VERSION ""

NS_ :

BS_:

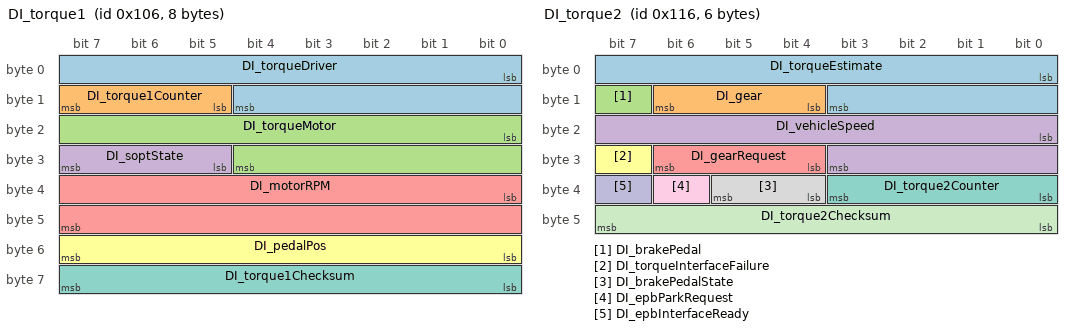
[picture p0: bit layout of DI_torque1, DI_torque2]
BO_ 262 DI_torque1: 8 DI
 SG_ DI_torqueDriver : 0|13@1- (0.25,0) [-750|750] "Nm"  NEO
 SG_ DI_torque1Counter : 13|3@1+ (1,0) [0|0] ""  NEO
 SG_ DI_torqueMotor : 16|13@1- (0.25,0) [-750|750] "Nm"  NEO
 SG_ DI_soptState : 29|3@1+ (1,0) [0|0] ""  NEO
 SG_ DI_motorRPM : 32|16@1- (1,0) [-17000|17000] "RPM"  NEO
 SG_ DI_pedalPos : 48|8@1+ (0.4,0) [0|100] "%"  NEO
 SG_ DI_torque1Checksum : 56|8@1+ (1,0) [0|0] ""  NEO

BO_ 278 DI_torque2: 6 DI
 SG_ DI_torqueEstimate : 0|12@1- (0.5,0) [-750|750] "Nm" NEO
 SG_ DI_gear : 12|3@1+ (1,0) [0|0] "" NEO
 SG_ DI_brakePedal : 15|1@1+ (1,0) [0|0] "" NEO
 SG_ DI_vehicleSpeed : 16|12@1+ (0.05,-25) [-25|179.75] "MPH" NEO
 SG_ DI_gearRequest : 28|3@1+ (1,0) [0|0] "" NEO
 SG_ DI_torqueInterfaceFailure : 31|1@1+ (1,0) [0|0] "" NEO
 SG_ DI_torque2Counter : 32|4@1+ (1,0) [0|0] "" NEO
 SG_ DI_brakePedalState : 36|2@1+ (1,0) [0|0] "" NEO
 SG_ DI_epbParkRequest : 38|1@1+ (1,0) [0|0] "" NEO
 SG_ DI_epbInterfaceReady : 39|1@1+ (1,0) [0|0] "" NEO
 SG_ DI_torque2Checksum : 40|8@1+ (1,0) [0|0] "" NEO

BO_ 504 BrakeMessage: 8 XXX
 SG_ driverBrakeStatus : 2|2@1+ (1,0) [0|3] "" XXX

BO_ 568 STW_ACTN_RQ: 8 STW
 SG_ SpdCtrlLvr_Stat : 0|6@1+ (1,0) [0|0] "" NEO
 SG_ VSL_Enbl_Rq : 6|1@1+ (1,0) [0|0] "" NEO
 SG_ SpdCtrlLvrStat_Inv : 7|1@1+ (1,0) [0|0] "" NEO
 SG_ DTR_Dist_Rq : 8|8@1+ (1,0) [0|200] "" NEO
 SG_ TurnIndLvr_Stat : 16|2@1+ (1,0) [0|0] "" NEO
 SG_ HiBmLvr_Stat : 18|2@1+ (1,0) [0|0] "" NEO
 SG_ WprWashSw_Psd : 20|2@1+ (1,0) [0|0] "" NEO
 SG_ WprWash_R_Sw_Posn_V2 : 22|2@1+ (1,0) [0|0] "" NEO
 SG_ StW_Lvr_Stat : 24|3@1+ (1,0) [0|0] "" NEO
 SG_ StW_Cond_Flt : 27|1@1+ (1,0) [0|0] "" NEO
 SG_ StW_Cond_Psd : 28|2@1+ (1,0) [0|0] "" NEO
 SG_ HrnSw_Psd : 30|2@1+ (1,0) [0|0] "" NEO
 SG_ StW_Sw00_Psd : 32|1@1+ (1,0) [0|0] "" NEO
 SG_ StW_Sw01_Psd : 33|1@1+ (1,0) [0|0] "" NEO
 SG_ StW_Sw02_Psd : 34|1@1+ (1,0) [0|0] "" NEO
 SG_ StW_Sw03_Psd : 35|1@1+ (1,0) [0|0] "" NEO
 SG_ StW_Sw04_Psd : 36|1@1+ (1,0) [0|0] "" NEO
 SG_ StW_Sw05_Psd : 37|1@1+ (1,0) [0|0] "" NEO
 SG_ StW_Sw06_Psd : 38|1@1+ (1,0) [0|0] "" NEO
 SG_ StW_Sw07_Psd : 39|1@1+ (1,0) [0|0] "" NEO
 SG_ StW_Sw08_Psd : 40|1@1+ (1,0) [0|0] "" NEO
 SG_ StW_Sw09_Psd : 41|1@1+ (1,0) [0|0] "" NEO
 SG_ StW_Sw10_Psd : 42|1@1+ (1,0) [0|0] "" NEO
 SG_ StW_Sw11_Psd : 43|1@1+ (1,0) [0|0] "" NEO
 SG_ StW_Sw12_Psd : 44|1@1+ (1,0) [0|0] "" NEO
 SG_ StW_Sw13_Psd : 45|1@1+ (1,0) [0|0] "" NEO
 SG_ StW_Sw14_Psd : 46|1@1+ (1,0) [0|0] "" NEO
 SG_ StW_Sw15_Psd : 47|1@1+ (1,0) [0|0] "" NEO
 SG_ WprSw6Posn : 48|3@1+ (1,0) [0|0] "" NEO
 SG_ MC_STW_ACTN_RQ : 52|4@1+ (1,0) [0|15] "" NEO
 SG_ CRC_STW_ACTN_RQ : 56|8@1+ (1,0) [0|0] "" NEO

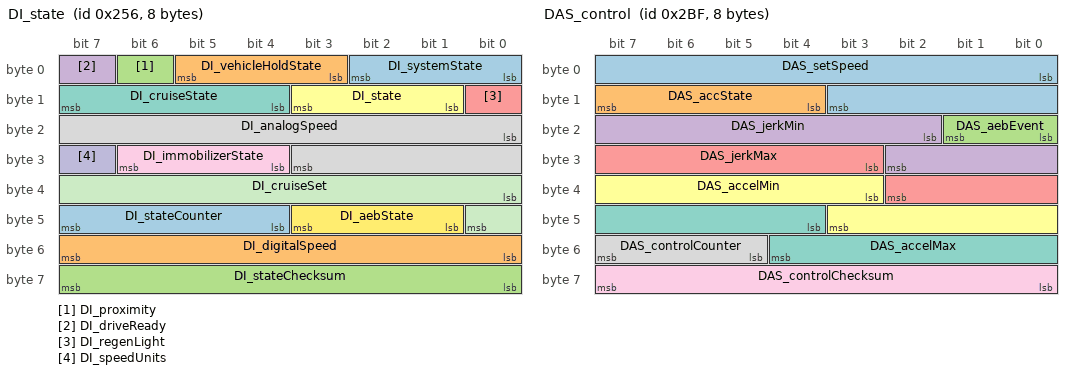
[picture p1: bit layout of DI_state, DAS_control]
BO_ 598 DI_state: 8 DI
 SG_ DI_systemState : 0|3@1+ (1,0) [0|0] ""  NEO
 SG_ DI_vehicleHoldState : 3|3@1+ (1,0) [0|0] ""  NEO
 SG_ DI_proximity : 6|1@1+ (1,0) [0|0] ""  NEO
 SG_ DI_driveReady : 7|1@1+ (1,0) [0|0] ""  NEO
 SG_ DI_regenLight : 8|1@1+ (1,0) [0|0] ""  NEO
 SG_ DI_state : 9|3@1+ (1,0) [0|0] ""  NEO
 SG_ DI_cruiseState : 12|4@1+ (1,0) [0|0] ""  NEO
 SG_ DI_analogSpeed : 16|12@1+ (0.1,0) [0|150] "speed"  NEO
 SG_ DI_immobilizerState : 28|3@1+ (1,0) [0|0] ""  NEO
 SG_ DI_speedUnits : 31|1@1+ (1,0) [0|1] ""  NEO
 SG_ DI_cruiseSet : 32|9@1+ (0.5,0) [0|255.5] "speed"  NEO
 SG_ DI_aebState : 41|3@1+ (1,0) [0|0] ""  NEO
 SG_ DI_stateCounter : 44|4@1+ (1,0) [0|0] ""  NEO
 SG_ DI_digitalSpeed : 48|8@1+ (1,0) [0|250] ""  NEO
 SG_ DI_stateChecksum : 56|8@1+ (1,0) [0|0] ""  NEO

BO_ 703 DAS_control: 8 GTW
 SG_ DAS_setSpeed : 0|12@1+ (0.1,0) [0|409.4] "kph" DI,PM,APS
 SG_ DAS_accState : 12|4@1+ (1,0) [0|0] "" DI,PM,APS
 SG_ DAS_aebEvent : 16|2@1+ (1,0) [0|3] "" DI,PM,APS
 SG_ DAS_jerkMin : 18|9@1+ (0.03,-15.232) [-15.232|0.098] "m/s^3" DI,PM,APS
 SG_ DAS_jerkMax : 27|8@1+ (0.059,0) [0|15.045] "m/s^3" DI,PM,APS
 SG_ DAS_accelMin : 35|9@1+ (0.04,-15) [-15|5.44] "m/s^2" DI,PM,APS
 SG_ DAS_accelMax : 44|9@1+ (0.04,-15) [-15|5.44] "m/s^2" DI,PM,APS
 SG_ DAS_controlCounter : 53|3@1+ (1,0) [0|0] "" DI,PM,APS
 SG_ DAS_controlChecksum : 56|8@1+ (1,0) [0|0] "" DI,PM,APS

BU_: XXX

CM_ "AUTOGENERATED FILE, DO NOT EDIT";

CM_ "Imported file _stellantis_common_ram_dt_generated.dbc starts here";
CM_ "Generated from _stellantis_common.dbc"

CM_ SG_ 258 STEERING_ANGLE_HP "Steering angle high precision";
CM_ SG_ 264 ENGINE_TORQUE "Effective engine torque";
CM_ SG_ 264 EXPECTED_ENGINE_TORQUE "Expected Engine Torque based on target engine speed";
CM_ SG_ 678 LKAS_ICON_COLOR "3 is yellow, 2 is green, 1 is white, 0 is null";
CM_ SG_ 678 LKAS_LANE_LINES "0x01 transparent lines, 0x02 left white, 0x03 right white, 0x04 left yellow with car on top, 0x05 left yellow with car on top, 0x06 both white, 0x07 left yellow, 0x08 left yellow right white, 0x09 right yellow, 0x0a right yellow left white, 0x0b left yellow with car on top right white, 0x0c right yellow with car on top left white, (0x00, 0x0d, 0x0e, 0x0f) null";
CM_ SG_ 678 LKAS_ALERTS "(0x01, 0x02) lane sense off, (0x03, 0x04, 0x06) place hands on steering wheel, 0x07 lane departure detected + place hands on steering wheel, (0x08, 0x09) lane sense unavailable + clean front windshield, 0x0b lane sense and auto high beam unavailable + clean front windshield, 0x0c lane sense unavailable + service required, (0x00, 0x05, 0x0a, 0x0d, 0x0e, 0x0f) null";

CM_ "chrysler_ram_dt.dbc starts here";

CM_ SG_ 133 ACTUAL_GEAR "0xd = P, 0x1-8 = D (actual gear), 0xb = R or N?? TODO find R vs N";
CM_ SG_ 153 ACC_Engaged "SENT BY FORWARD CAMERA 1 = ACTIVE, 3 = ENGAGED, 0 = DISENGAGED/OFF";
CM_ SG_ 166 LKAS_CONTROL_BIT "0=IDLE, 1=HAS 2=LKAS 3=ABSD, 4=TJA, 7=SNA";
CM_ SG_ 250 Auto_High_Beam "1 = HIGH BEAMS OK 0 = HIGH BEAMS OFF ";
CM_ SG_ 250 LKAS_LANE_LINES "9 = LEFT CAUTION, 11 = VERY LEFT CAUTION 10 = RIGHT CAUTION, 14 = VERY RIGHT, 4 = NO LINES DETECTED, 3 = LINES DETECTED, SYSTEM ACTIVE";
CM_ SG_ 464 Driver_Seatbelt_Status "1 unbuckled 0 buckled";
VAL_ 328 Gear 0 "N" 1 "D" 2 "D" 3 "D" 4 "D" 5 "D" 6 "D" 14 "R" 15 "P";
